# PIC32MX675F512H register map
Vendor: Microchip
Registers are 32-bit, read-write, reset 0x0 unless marked. A register's access mark holds for its fields unless they carry their own. Addresses are absolute, and some are shared; only a register's first bit layout is shown; [hi:lo] are bit positions.

## DMAC5
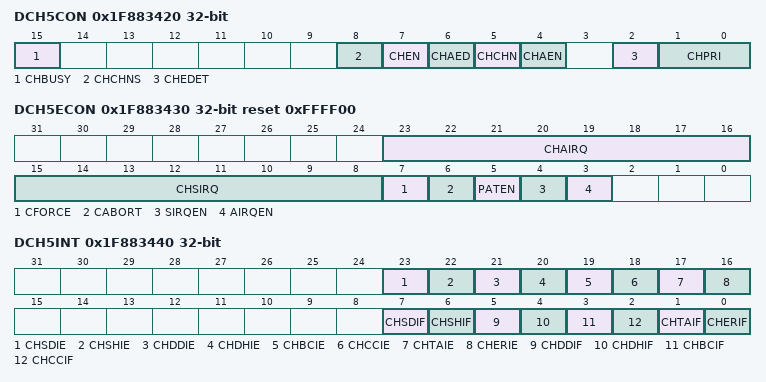
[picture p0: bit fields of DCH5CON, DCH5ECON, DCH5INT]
0x1F883420 DCH5CON reset not defined — (power-on value ----------------x------00000-000)
  [15] CHBUSY, [8] CHCHNS, [7] CHEN, [6] CHAED, [5] CHCHN, [4] CHAEN, [2] CHEDET ro, [1:0] CHPRI
0x1F883430 DCH5ECON reset 0xFFFF00
  [23:16] CHAIRQ
  [15:8] CHSIRQ
  [7] CFORCE — (can only be set)
  [6] CABORT — (can only be set)
  [5] PATEN
  [4] SIRQEN
  [3] AIRQEN
0x1F883440 DCH5INT
  [23] CHSDIE, [22] CHSHIE, [21] CHDDIE, [20] CHDHIE, [19] CHBCIE, [18] CHCCIE, [17] CHTAIE, [16] CHERIE, [7] CHSDIF, [6] CHSHIF, [5] CHDDIF, [4] CHDHIF, [3] CHBCIF, [2] CHCCIF, [1] CHTAIF, [0] CHERIF
0x1F883450 DCH5SSA reset not defined — (power-on value xxxxxxxxxxxxxxxxxxxxxxxxxxxxxxxx)
0x1F883460 DCH5DSA reset not defined — (power-on value xxxxxxxxxxxxxxxxxxxxxxxxxxxxxxxx)
0x1F883470 DCH5SSIZ reset not defined — (power-on value ----------------xxxxxxxxxxxxxxxx)
  [15:0] CHSSIZ
0x1F883480 DCH5DSIZ reset not defined — (power-on value ----------------xxxxxxxxxxxxxxxx)
  [15:0] CHDSIZ
0x1F883490 DCH5SPTR reset not defined — (power-on value ----------------xxxxxxxxxxxxxxxx)
  [15:0] CHSPTR
0x1F8834A0 DCH5DPTR ro
  [15:0] CHDPTR
0x1F8834B0 DCH5CSIZ reset not defined — (power-on value ----------------xxxxxxxxxxxxxxxx)
  [15:0] CHCSIZ
0x1F8834C0 DCH5CPTR reset not defined — (power-on value ----------------xxxxxxxxxxxxxxxx)
  [15:0] CHCPTR
0x1F8834D0 DCH5DAT reset not defined — (power-on value ------------------------xxxxxxxx)
  [7:0] DCHPDAT

## DMAC6
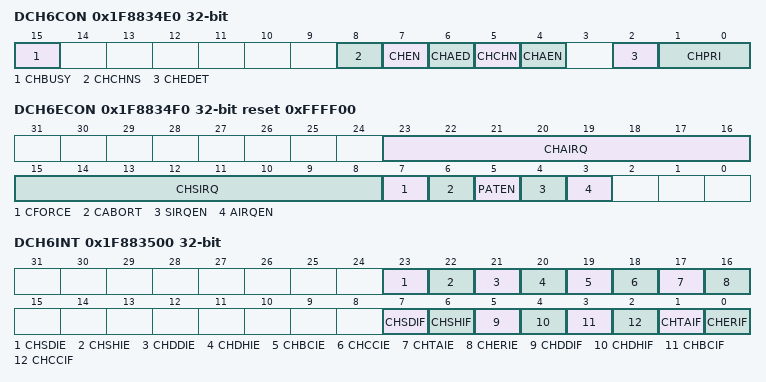
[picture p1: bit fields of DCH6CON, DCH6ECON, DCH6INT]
0x1F8834E0 DCH6CON reset not defined — (power-on value ----------------x------00000-000)
  [15] CHBUSY, [8] CHCHNS, [7] CHEN, [6] CHAED, [5] CHCHN, [4] CHAEN, [2] CHEDET ro, [1:0] CHPRI
0x1F8834F0 DCH6ECON reset 0xFFFF00
  [23:16] CHAIRQ
  [15:8] CHSIRQ
  [7] CFORCE — (can only be set)
  [6] CABORT — (can only be set)
  [5] PATEN
  [4] SIRQEN
  [3] AIRQEN
0x1F883500 DCH6INT
  [23] CHSDIE, [22] CHSHIE, [21] CHDDIE, [20] CHDHIE, [19] CHBCIE, [18] CHCCIE, [17] CHTAIE, [16] CHERIE, [7] CHSDIF, [6] CHSHIF, [5] CHDDIF, [4] CHDHIF, [3] CHBCIF, [2] CHCCIF, [1] CHTAIF, [0] CHERIF
0x1F883510 DCH6SSA reset not defined — (power-on value xxxxxxxxxxxxxxxxxxxxxxxxxxxxxxxx)
0x1F883520 DCH6DSA reset not defined — (power-on value xxxxxxxxxxxxxxxxxxxxxxxxxxxxxxxx)
0x1F883530 DCH6SSIZ reset not defined — (power-on value ----------------xxxxxxxxxxxxxxxx)
  [15:0] CHSSIZ
0x1F883540 DCH6DSIZ reset not defined — (power-on value ----------------xxxxxxxxxxxxxxxx)
  [15:0] CHDSIZ
0x1F883550 DCH6SPTR reset not defined — (power-on value ----------------xxxxxxxxxxxxxxxx)
  [15:0] CHSPTR
0x1F883560 DCH6DPTR ro
  [15:0] CHDPTR
0x1F883570 DCH6CSIZ reset not defined — (power-on value ----------------xxxxxxxxxxxxxxxx)
  [15:0] CHCSIZ
0x1F883580 DCH6CPTR reset not defined — (power-on value ----------------xxxxxxxxxxxxxxxx)
  [15:0] CHCPTR
0x1F883590 DCH6DAT reset not defined — (power-on value ------------------------xxxxxxxx)
  [7:0] DCHPDAT

## DMAC7
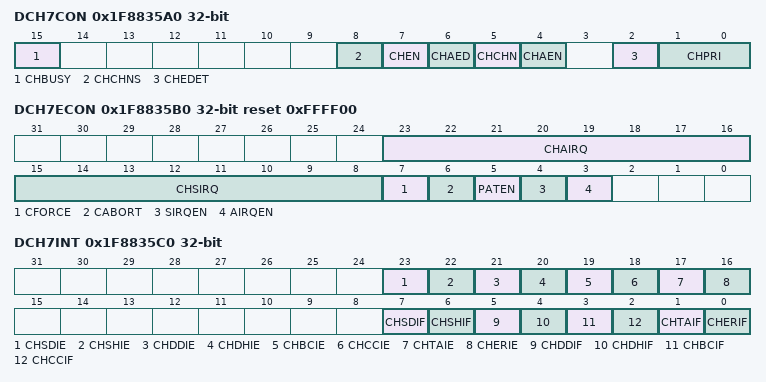
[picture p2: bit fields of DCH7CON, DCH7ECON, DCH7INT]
0x1F8835A0 DCH7CON reset not defined — (power-on value ----------------x------00000-000)
  [15] CHBUSY, [8] CHCHNS, [7] CHEN, [6] CHAED, [5] CHCHN, [4] CHAEN, [2] CHEDET ro, [1:0] CHPRI
0x1F8835B0 DCH7ECON reset 0xFFFF00
  [23:16] CHAIRQ
  [15:8] CHSIRQ
  [7] CFORCE — (can only be set)
  [6] CABORT — (can only be set)
  [5] PATEN
  [4] SIRQEN
  [3] AIRQEN
0x1F8835C0 DCH7INT
  [23] CHSDIE, [22] CHSHIE, [21] CHDDIE, [20] CHDHIE, [19] CHBCIE, [18] CHCCIE, [17] CHTAIE, [16] CHERIE, [7] CHSDIF, [6] CHSHIF, [5] CHDDIF, [4] CHDHIF, [3] CHBCIF, [2] CHCCIF, [1] CHTAIF, [0] CHERIF
0x1F8835D0 DCH7SSA reset not defined — (power-on value xxxxxxxxxxxxxxxxxxxxxxxxxxxxxxxx)
0x1F8835E0 DCH7DSA reset not defined — (power-on value xxxxxxxxxxxxxxxxxxxxxxxxxxxxxxxx)
0x1F8835F0 DCH7SSIZ reset not defined — (power-on value ----------------xxxxxxxxxxxxxxxx)
  [15:0] CHSSIZ
0x1F883600 DCH7DSIZ reset not defined — (power-on value ----------------xxxxxxxxxxxxxxxx)
  [15:0] CHDSIZ
0x1F883610 DCH7SPTR reset not defined — (power-on value ----------------xxxxxxxxxxxxxxxx)
  [15:0] CHSPTR
0x1F883620 DCH7DPTR ro
  [15:0] CHDPTR
0x1F883630 DCH7CSIZ reset not defined — (power-on value ----------------xxxxxxxxxxxxxxxx)
  [15:0] CHCSIZ
0x1F883640 DCH7CPTR reset not defined — (power-on value ----------------xxxxxxxxxxxxxxxx)
  [15:0] CHCPTR
0x1F883650 DCH7DAT reset not defined — (power-on value ------------------------xxxxxxxx)
  [7:0] DCHPDAT
